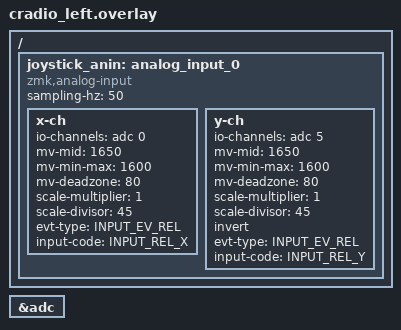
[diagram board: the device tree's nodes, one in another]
/*
 * Joystick hardware on LEFT half (central / USB side)
 *
 * Wiring (nice!nano / nRF52840):
 *   VCC -> 3V3
 *   GND -> GND
 *   VRx -> P0.02  (ADC channel 0)
 *   VRy -> P0.29  (ADC channel 5)
 *
 * Arrow key mapping is in cradio.keymap (needs keys.h preprocessing).
 */

#include <zephyr/dt-bindings/input/input-event-codes.h>

&adc {
	status = "okay";
};

/ {
	joystick_anin: analog_input_0 {
		compatible = "zmk,analog-input";
		sampling-hz = <50>;
		x-ch {
			io-channels = <&adc 0>;
			mv-mid = <1650>;
			mv-min-max = <1600>;
			mv-deadzone = <80>;
			scale-multiplier = <1>;
			scale-divisor = <45>;
			evt-type = <INPUT_EV_REL>;
			input-code = <INPUT_REL_X>;
		};
		y-ch {
			io-channels = <&adc 5>;
			mv-mid = <1650>;
			mv-min-max = <1600>;
			mv-deadzone = <80>;
			scale-multiplier = <1>;
			scale-divisor = <45>;
			invert;
			evt-type = <INPUT_EV_REL>;
			input-code = <INPUT_REL_Y>;
		};
	};
};
